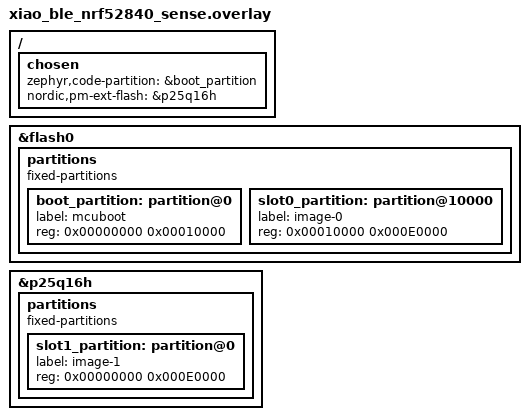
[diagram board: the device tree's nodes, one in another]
/*
 * MCUboot overlay for Seeed XIAO BLE Sense
 *
 * The stock XIAO BLE DTS uses an Adafruit-layout (sd_partition, code_partition,
 * boot_partition at 0xF4000). We delete those and replace with MCUboot labels
 * that match our pm_static layout:
 *   boot_partition  : 0x00000 – 0x10000  (64 KB, MCUboot itself)
 *   slot0_partition : 0x10000 – 0xF0000  (896 KB, primary app)
 *   slot1_partition : p25q16h 0x0 – 0xE0000 (896 KB, external QSPI secondary)
 *
 * MCUboot's cmake needs slot0_partition to exist in its own DTS so it can
 * walk up two parent levels and read erase-block-size from the flash controller.
 * slot1_partition is also needed so the paths differ and the cmake code doesn't
 * fall into the "same device" branch that calls dt_prop with an empty PATH.
 */

&flash0 {
    /delete-node/ partitions;

    partitions {
        compatible = "fixed-partitions";
        #address-cells = <1>;
        #size-cells = <1>;

        boot_partition: partition@0 {
            label = "mcuboot";
            reg = <0x00000000 0x00010000>;
        };

        slot0_partition: partition@10000 {
            label = "image-0";
            reg = <0x00010000 0x000E0000>;
        };
    };
};

/* Secondary slot lives in the on-board QSPI NOR flash */
&p25q16h {
    partitions {
        compatible = "fixed-partitions";
        #address-cells = <1>;
        #size-cells = <1>;

        slot1_partition: partition@0 {
            label = "image-1";
            reg = <0x00000000 0x000E0000>;
        };
    };
};

/ {
    chosen {
        zephyr,code-partition = &boot_partition;
        nordic,pm-ext-flash = &p25q16h;
    };
};
